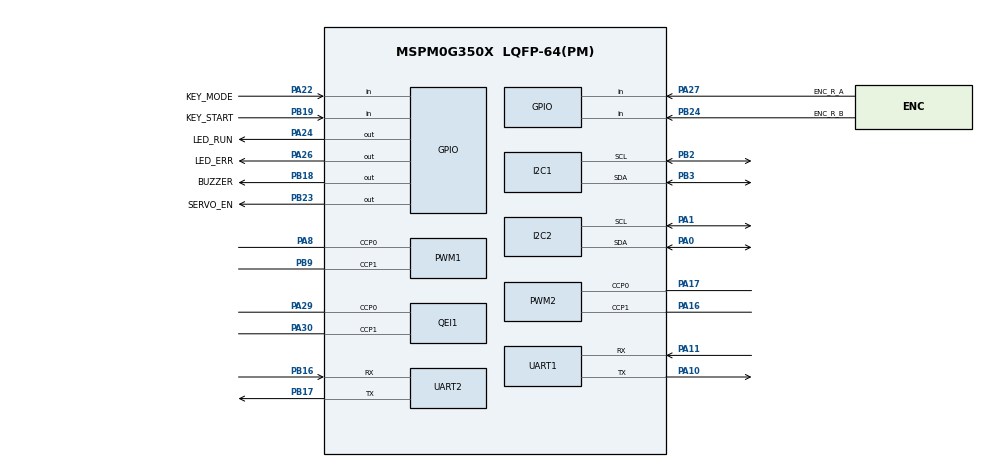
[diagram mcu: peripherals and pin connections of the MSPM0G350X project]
/**
 * @cliArgs --device "MSPM0G350X" --part "Default" --package "LQFP-64(PM)" --product "mspm0_sdk@2.10.00.04"
 * @versions {"tool":"1.26.2+4477"}
 */

/**
 * Import the modules used in this configuration.
 */
const GPIO    = scripting.addModule("/ti/driverlib/GPIO", {}, false);
const GPIO1   = GPIO.addInstance();
const GPIO2   = GPIO.addInstance();
const GPIO3   = GPIO.addInstance();
const GPIO4   = GPIO.addInstance();
const GPIO5   = GPIO.addInstance();
const I2C     = scripting.addModule("/ti/driverlib/I2C", {}, false);
const I2C1    = I2C.addInstance();
const I2C2    = I2C.addInstance();
const PWM     = scripting.addModule("/ti/driverlib/PWM", {}, false);
const PWM1    = PWM.addInstance();
const PWM2    = PWM.addInstance();
const QEI     = scripting.addModule("/ti/driverlib/QEI", {}, false);
const QEI1    = QEI.addInstance();
const SYSCTL  = scripting.addModule("/ti/driverlib/SYSCTL");
const SYSTICK = scripting.addModule("/ti/driverlib/SYSTICK");
const UART    = scripting.addModule("/ti/driverlib/UART", {}, false);
const UART1   = UART.addInstance();
const UART2   = UART.addInstance();

/**
 * Write custom configuration values to the imported modules.
 */
GPIO1.$name                          = "GPIO_LED";
GPIO1.associatedPins[0].$name        = "HEART";
GPIO1.associatedPins[0].assignedPort = "PORTB";
GPIO1.associatedPins[0].assignedPin  = "26";

const Board = scripting.addModule("/ti/driverlib/Board", {}, false);

GPIO2.$name                         = "MOTOR_A";
GPIO2.port                          = "PORTA";
GPIO2.associatedPins.create(2);
GPIO2.associatedPins[0].$name       = "AIN1";
GPIO2.associatedPins[0].assignedPin = "12";
GPIO2.associatedPins[1].$name       = "AIN2";
GPIO2.associatedPins[1].assignedPin = "13";

GPIO3.$name                         = "MOTOR_B";
GPIO3.port                          = "PORTB";
GPIO3.associatedPins.create(3);
GPIO3.associatedPins[0].$name       = "BIN1";
GPIO3.associatedPins[0].assignedPin = "6";
GPIO3.associatedPins[1].$name       = "BIN2";
GPIO3.associatedPins[1].assignedPin = "7";
GPIO3.associatedPins[2].$name       = "STBY";
GPIO3.associatedPins[2].assignedPin = "0";

GPIO4.$name                              = "GPIO_IOA";
GPIO4.port                               = "PORTA";
GPIO4.associatedPins.create(4);
GPIO4.associatedPins[0].$name            = "KEY_MODE";
GPIO4.associatedPins[0].direction        = "INPUT";
GPIO4.associatedPins[0].ioStructure      = "SD";
GPIO4.associatedPins[0].internalResistor = "PULL_UP";
GPIO4.associatedPins[0].pin.$assign      = "PA22";
GPIO4.associatedPins[1].$name            = "LED_RUN";
GPIO4.associatedPins[1].pin.$assign      = "PA24";
GPIO4.associatedPins[2].$name            = "LED_ERR";
GPIO4.associatedPins[2].pin.$assign      = "PA26";
GPIO4.associatedPins[3].$name            = "ENC_R_A";
GPIO4.associatedPins[3].direction        = "INPUT";
GPIO4.associatedPins[3].interruptEn      = true;
GPIO4.associatedPins[3].polarity         = "RISE";
GPIO4.associatedPins[3].assignedPin      = "27";
GPIO4.associatedPins[3].pin.$assign      = "PA27";

GPIO5.$name                              = "GPIO_IOB";
GPIO5.port                               = "PORTB";
GPIO5.associatedPins.create(4);
GPIO5.associatedPins[0].$name            = "BUZZER";
GPIO5.associatedPins[0].initialValue     = "SET";
GPIO5.associatedPins[0].pin.$assign      = "PB18";
GPIO5.associatedPins[1].$name            = "KEY_START";
GPIO5.associatedPins[1].direction        = "INPUT";
GPIO5.associatedPins[1].internalResistor = "PULL_UP";
GPIO5.associatedPins[1].pin.$assign      = "PB19";
GPIO5.associatedPins[2].$name            = "SERVO_EN";
GPIO5.associatedPins[2].pin.$assign      = "PB23";
GPIO5.associatedPins[3].$name            = "ENC_R_B";
GPIO5.associatedPins[3].direction        = "INPUT";
GPIO5.associatedPins[3].pin.$assign      = "PB24";

I2C1.$name                             = "I2C_BUS";
I2C1.basicEnableController             = true;
I2C1.peripheral.$assign                = "I2C1";
I2C1.peripheral.sdaPin.$assign         = "PB3";
I2C1.peripheral.sclPin.$assign         = "PB2";
I2C1.sdaPinConfig.hideOutputInversion  = scripting.forceWrite(false);
I2C1.sdaPinConfig.onlyInternalResistor = scripting.forceWrite(false);
I2C1.sdaPinConfig.passedPeripheralType = scripting.forceWrite("Digital");
I2C1.sdaPinConfig.$name                = "ti_driverlib_gpio_GPIOPinGeneric8";
I2C1.sclPinConfig.hideOutputInversion  = scripting.forceWrite(false);
I2C1.sclPinConfig.onlyInternalResistor = scripting.forceWrite(false);
I2C1.sclPinConfig.passedPeripheralType = scripting.forceWrite("Digital");
I2C1.sclPinConfig.$name                = "ti_driverlib_gpio_GPIOPinGeneric9";

I2C2.$name                             = "I2C_IMU";
I2C2.basicEnableController             = true;
I2C2.peripheral.$assign                = "I2C0";
I2C2.peripheral.sdaPin.$assign         = "PA0";
I2C2.peripheral.sclPin.$assign         = "PA1";
I2C2.sdaPinConfig.$name                = "ti_driverlib_gpio_GPIOPinGeneric12";
I2C2.sdaPinConfig.hideOutputInversion  = scripting.forceWrite(false);
I2C2.sdaPinConfig.onlyInternalResistor = scripting.forceWrite(false);
I2C2.sdaPinConfig.passedPeripheralType = scripting.forceWrite("Digital");
I2C2.sclPinConfig.$name                = "ti_driverlib_gpio_GPIOPinGeneric13";
I2C2.sclPinConfig.hideOutputInversion  = scripting.forceWrite(false);
I2C2.sclPinConfig.onlyInternalResistor = scripting.forceWrite(false);
I2C2.sclPinConfig.passedPeripheralType = scripting.forceWrite("Digital");

PWM1.$name                              = "PWM_MOTOR";
PWM1.timerCount                         = 1600;
PWM1.peripheral.ccp0Pin.$assign         = "PA8";
PWM1.peripheral.ccp1Pin.$assign         = "PB9";
PWM1.PWM_CHANNEL_0.$name                = "ti_driverlib_pwm_PWMTimerCC0";
PWM1.PWM_CHANNEL_1.$name                = "ti_driverlib_pwm_PWMTimerCC1";
PWM1.ccp0PinConfig.$name                = "ti_driverlib_gpio_GPIOPinGeneric2";
PWM1.ccp0PinConfig.direction            = scripting.forceWrite("OUTPUT");
PWM1.ccp0PinConfig.hideOutputInversion  = scripting.forceWrite(false);
PWM1.ccp0PinConfig.onlyInternalResistor = scripting.forceWrite(false);
PWM1.ccp0PinConfig.passedPeripheralType = scripting.forceWrite("Digital");
PWM1.ccp1PinConfig.$name                = "ti_driverlib_gpio_GPIOPinGeneric3";
PWM1.ccp1PinConfig.direction            = scripting.forceWrite("OUTPUT");
PWM1.ccp1PinConfig.hideOutputInversion  = scripting.forceWrite(false);
PWM1.ccp1PinConfig.onlyInternalResistor = scripting.forceWrite(false);
PWM1.ccp1PinConfig.passedPeripheralType = scripting.forceWrite("Digital");

PWM2.$name                              = "PWM_SERVO";
PWM2.clockDivider                       = 8;
PWM2.clockPrescale                      = 2;
PWM2.timerCount                         = 40000;
PWM2.peripheral.$assign                 = "TIMA1";
PWM2.peripheral.ccp0Pin.$assign         = "PA17";
PWM2.peripheral.ccp1Pin.$assign         = "PA16";
PWM2.PWM_CHANNEL_0.$name                = "ti_driverlib_pwm_PWMTimerCC2";
PWM2.PWM_CHANNEL_1.$name                = "ti_driverlib_pwm_PWMTimerCC3";
PWM2.ccp0PinConfig.$name                = "ti_driverlib_gpio_GPIOPinGeneric4";
PWM2.ccp0PinConfig.direction            = scripting.forceWrite("OUTPUT");
PWM2.ccp0PinConfig.hideOutputInversion  = scripting.forceWrite(false);
PWM2.ccp0PinConfig.onlyInternalResistor = scripting.forceWrite(false);
PWM2.ccp0PinConfig.passedPeripheralType = scripting.forceWrite("Digital");
PWM2.ccp1PinConfig.$name                = "ti_driverlib_gpio_GPIOPinGeneric5";
PWM2.ccp1PinConfig.direction            = scripting.forceWrite("OUTPUT");
PWM2.ccp1PinConfig.hideOutputInversion  = scripting.forceWrite(false);
PWM2.ccp1PinConfig.onlyInternalResistor = scripting.forceWrite(false);
PWM2.ccp1PinConfig.passedPeripheralType = scripting.forceWrite("Digital");

QEI1.$name                              = "QEI_ENC_L";
QEI1.peripheral.$assign                 = "TIMG8";
QEI1.peripheral.ccp0Pin.$assign         = "PA29";
QEI1.peripheral.ccp1Pin.$assign         = "PA30";
QEI1.ccp0PinConfig.hideOutputInversion  = scripting.forceWrite(false);
QEI1.ccp0PinConfig.onlyInternalResistor = scripting.forceWrite(false);
QEI1.ccp0PinConfig.passedPeripheralType = scripting.forceWrite("Digital");
QEI1.ccp0PinConfig.$name                = "ti_driverlib_gpio_GPIOPinGeneric10";
QEI1.ccp1PinConfig.hideOutputInversion  = scripting.forceWrite(false);
QEI1.ccp1PinConfig.onlyInternalResistor = scripting.forceWrite(false);
QEI1.ccp1PinConfig.passedPeripheralType = scripting.forceWrite("Digital");
QEI1.ccp1PinConfig.$name                = "ti_driverlib_gpio_GPIOPinGeneric11";

SYSCTL.forceDefaultClkConfig = true;

SYSTICK.interruptEnable = true;
SYSTICK.periodEnable    = true;
SYSTICK.systickEnable   = true;
SYSTICK.period          = 32000;

UART1.$name                            = "UART_VOFA";
UART1.targetBaudRate                   = 115200;
UART1.enableFIFO                       = true;
UART1.peripheral.$assign               = "UART0";
UART1.peripheral.rxPin.$assign         = "PA11";
UART1.peripheral.txPin.$assign         = "PA10";
UART1.txPinConfig.direction            = scripting.forceWrite("OUTPUT");
UART1.txPinConfig.hideOutputInversion  = scripting.forceWrite(false);
UART1.txPinConfig.onlyInternalResistor = scripting.forceWrite(false);
UART1.txPinConfig.passedPeripheralType = scripting.forceWrite("Digital");
UART1.txPinConfig.$name                = "ti_driverlib_gpio_GPIOPinGeneric0";
UART1.rxPinConfig.hideOutputInversion  = scripting.forceWrite(false);
UART1.rxPinConfig.onlyInternalResistor = scripting.forceWrite(false);
UART1.rxPinConfig.passedPeripheralType = scripting.forceWrite("Digital");
UART1.rxPinConfig.$name                = "ti_driverlib_gpio_GPIOPinGeneric1";

UART2.$name                            = "UART_K230";
UART2.targetBaudRate                   = 115200;
UART2.enabledInterrupts                = ["RX"];
UART2.peripheral.$assign               = "UART2";
UART2.peripheral.rxPin.$assign         = "PB16";
UART2.peripheral.txPin.$assign         = "PB17";
UART2.txPinConfig.direction            = scripting.forceWrite("OUTPUT");
UART2.txPinConfig.hideOutputInversion  = scripting.forceWrite(false);
UART2.txPinConfig.onlyInternalResistor = scripting.forceWrite(false);
UART2.txPinConfig.passedPeripheralType = scripting.forceWrite("Digital");
UART2.txPinConfig.$name                = "ti_driverlib_gpio_GPIOPinGeneric6";
UART2.rxPinConfig.hideOutputInversion  = scripting.forceWrite(false);
UART2.rxPinConfig.onlyInternalResistor = scripting.forceWrite(false);
UART2.rxPinConfig.passedPeripheralType = scripting.forceWrite("Digital");
UART2.rxPinConfig.$name                = "ti_driverlib_gpio_GPIOPinGeneric7";

/**
 * Pinmux solution for unlocked pins/peripherals. This ensures that minor changes to the automatic solver in a future
 * version of the tool will not impact the pinmux you originally saw.  These lines can be completely deleted in order to
 * re-solve from scratch.
 */
GPIO1.associatedPins[0].pin.$suggestSolution = "PB26";
Board.peripheral.$suggestSolution            = "DEBUGSS";
Board.peripheral.swclkPin.$suggestSolution   = "PA20";
Board.peripheral.swdioPin.$suggestSolution   = "PA19";
GPIO2.associatedPins[0].pin.$suggestSolution = "PA12";
GPIO2.associatedPins[1].pin.$suggestSolution = "PA13";
GPIO3.associatedPins[0].pin.$suggestSolution = "PB6";
GPIO3.associatedPins[1].pin.$suggestSolution = "PB7";
GPIO3.associatedPins[2].pin.$suggestSolution = "PB0";
PWM1.peripheral.$suggestSolution             = "TIMA0";
SYSCTL.peripheral.$suggestSolution           = "SYSCTL";
